# A31C15x register map
Vendor: ABOV Semiconductor Co., Ltd.; File version: 1.0
CPU: CM0PLUS r0p1, little endian, no MPU, no FPU, VTOR, 2 interrupt priority bits
Registers are 32-bit, read-write, reset 0x0 unless marked. A register's access mark holds for its fields unless they carry their own. Offsets are from the block's base; [hi:lo] are bit positions; {n}, {i} and the like mark numbered series.

## DFMC — DATA FLASH MEMORY CONTROLLER
Base 0x40081000
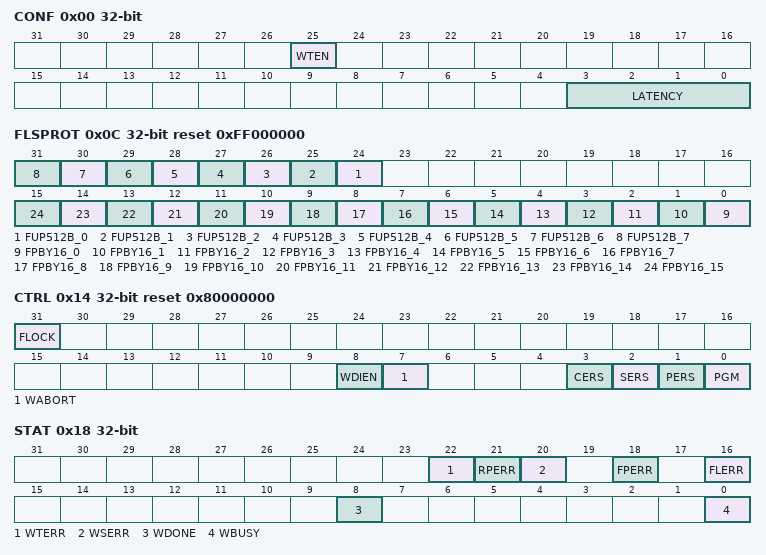
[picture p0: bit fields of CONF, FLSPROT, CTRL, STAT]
0x00 CONF — Data Flash Memory Config Register
  [25] WTEN — Whether to Enable or Disable the Data Flash Write
  [3:0] LATENCY — Flash Wait Value Bits
0x04 FLSKEY wo — Data Flash Memory Access Key Register
  [31:0] FKEY — Flash Memory Access Key, KEY1(0x01234567) -> KEY2(0x12345678) -> KEY3(0x23456789)
0x0C FLSPROT reset 0xFF000000 — Data Flash Memory Protection Register
  [n+24] FUP512B_{n} (n=0..7) — Flash upper 4KB Unprotection
  [n] FPBY16_{n} (n=0..15) — Flash 2KB Protection
0x14 CTRL reset 0x80000000 — Data Flash Access Control Register
  [31] FLOCK — Flash Memory Lock Bit
  [8] WDIEN — Whether to Enable or Disable the Write Done Interrupt
    0=Disable interrupt; 1=Enable interrupt
  [7] WABORT — Abort write operation
    0=Disable (No Effect); 1=Enable (Abort write operaton)
  [3] CERS — Flash Memory Bulk(Chip) Erase Mode
    0=Disable bulk erase; 1=Enable bulk erase
  [2] SERS — Flash Memory Sector (2KB) Erase Mode
    0=Disable sector erase; 1=Enable sector erase
  [1] PERS — Flash Memory Page (512 Bytes) Erase Mode
    0=Disable page erase; 1=Enable page erase
  [0] PGM — Flash Memory Write Mode
    0=Disable write mode; 1=Enable write mode
0x18 STAT — Data Flash Access Status Register
  [22] WTERR — Wrtie Timeout Error (Cleared by writing a '1' )
  [21] RPERR — Read Protect Error (Cleared by writing a '1' )
  [20] WSERR — Write Sequence Error (Cleared by writing a '1' )
  [18] FPERR — Flash Protect Error (Cleared by writing a '1' )
  [16] FLERR — Flash Lock Error (Cleared by writing a '1' )
  [8] WDONE — Write Done Check (Cleared by writing a '1' )
  [0] WBUSY ro — Write Busy Check
    0=Not_Busy (Checksum Not Busy); 1=Busy (Checksum Busy)
0x40 WTIMEOUT — Data Flash Write Timeout Register
  [31:0] WTIMEOUT — Write timeout count

## DMA0 — Direct Memory Access Control 0
Base 0x40000400
Same registers: DMA1 0x40000410, DMA2 0x40000420, DMA3 0x40000430, DMA4 0x40000440, DMA5 0x40000450, DMA6 0x40000460, DMA7 0x40000470
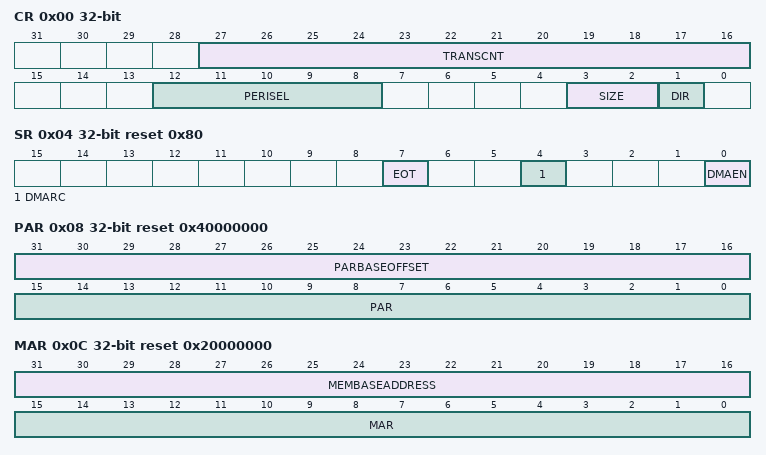
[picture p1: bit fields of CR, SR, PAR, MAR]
0x00 CR — DMA channel n control register
  [27:16] TRANSCNT — Number of DMA transfers Before enabling
  [12:8] PERISEL — Peripheral selection
  [3:2] SIZE — Bus transfer size
    0=Byte (transmit byte size); 1=half_word (transmit half word size); 2=word (transmit word size)
  [1] DIR — Transfer direction selection
    0=MEM-PERI (Memory->Peripheral); 1=PERI-MEM (Peripheral->Memory)
0x04 SR reset 0x80 — DMA channel n status register
  [7] EOT ro — Transfer ends
    0=BUSY (Transmit data is Busy); 1=EMPTY (Transmit complete)
  [4] DMARC — DMA request clear (Auto clear)
    1=Clear (DMA Clear)
  [0] DMAEN — Enables DMA use
0x08 PAR reset 0x40000000 — DMA channel n peripheral address register
  [31:16] PARBASEOFFSET ro — Peripheral base address offset
  [15:0] PAR — Address of the transfer / receive buffers target peripheral
0x0C MAR reset 0x20000000 — DMA channel n memory address register
  [31:16] MEMBASEADDRESS ro — Memory base address offset
  [15:0] MAR — Target memory address of the data transfer

## WDT — WATCH-DOG TIMER
Base 0x40000200
0x00 LR — WDT load register
  [31:0] LR — WDT load value register
0x04 CNT reset 0x9C4 — WDT current count register
  [31:0] CNT ro — WDT current counter register
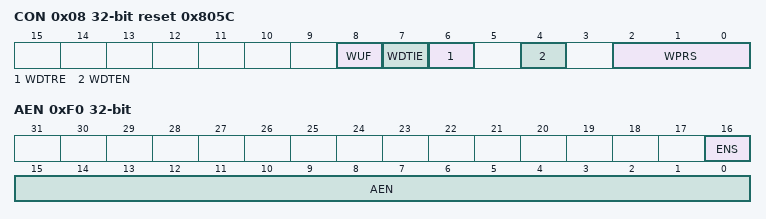
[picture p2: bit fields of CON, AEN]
0x08 CON reset 0x805C — WDT control register
  [8] WUF — WDT underflow flag (The bit is cleared when WDT_LR is written.)
  [7] WDTIE — Whether to enable or disable the WDT counter underflow interrupt
  [6] WDTRE — Whether to enable or disable the WDT counter underflow reset
  [4] WDTEN — Whether to enable or disable the WDT counter
  [2:0] WPRS — Counter clock prescaler
    0=WDTCLKIN_DIV_BY_1 (WDT Input Clock divide by 1); 1=WDTCLKIN_DIV_BY_4 (WDT Input Clock divide by 4); 2=WDTCLKIN_DIV_BY_8 (WDT Input Clock divide by 8); 3=WDTCLKIN_DIV_BY_16 (WDT Input Clock divide by 16); 4=WDTCLKIN_DIV_BY_32 (WDT Input Clock divide by 32); 5=WDTCLKIN_DIV_BY_64 (WDT Input Clock divide by 64); 6=WDTCLKIN_DIV_BY_128 (WDT Input Clock divide by 128); 7=WDTCLKIN_DIV_BY_256 (WDT Input Clock divide by 256)
0xF0 AEN — WDT access enable register
  [16] ENS ro — Enable status bit
  [15:0] AEN wo — Enable the write access of WDT registers (0xA55A)
